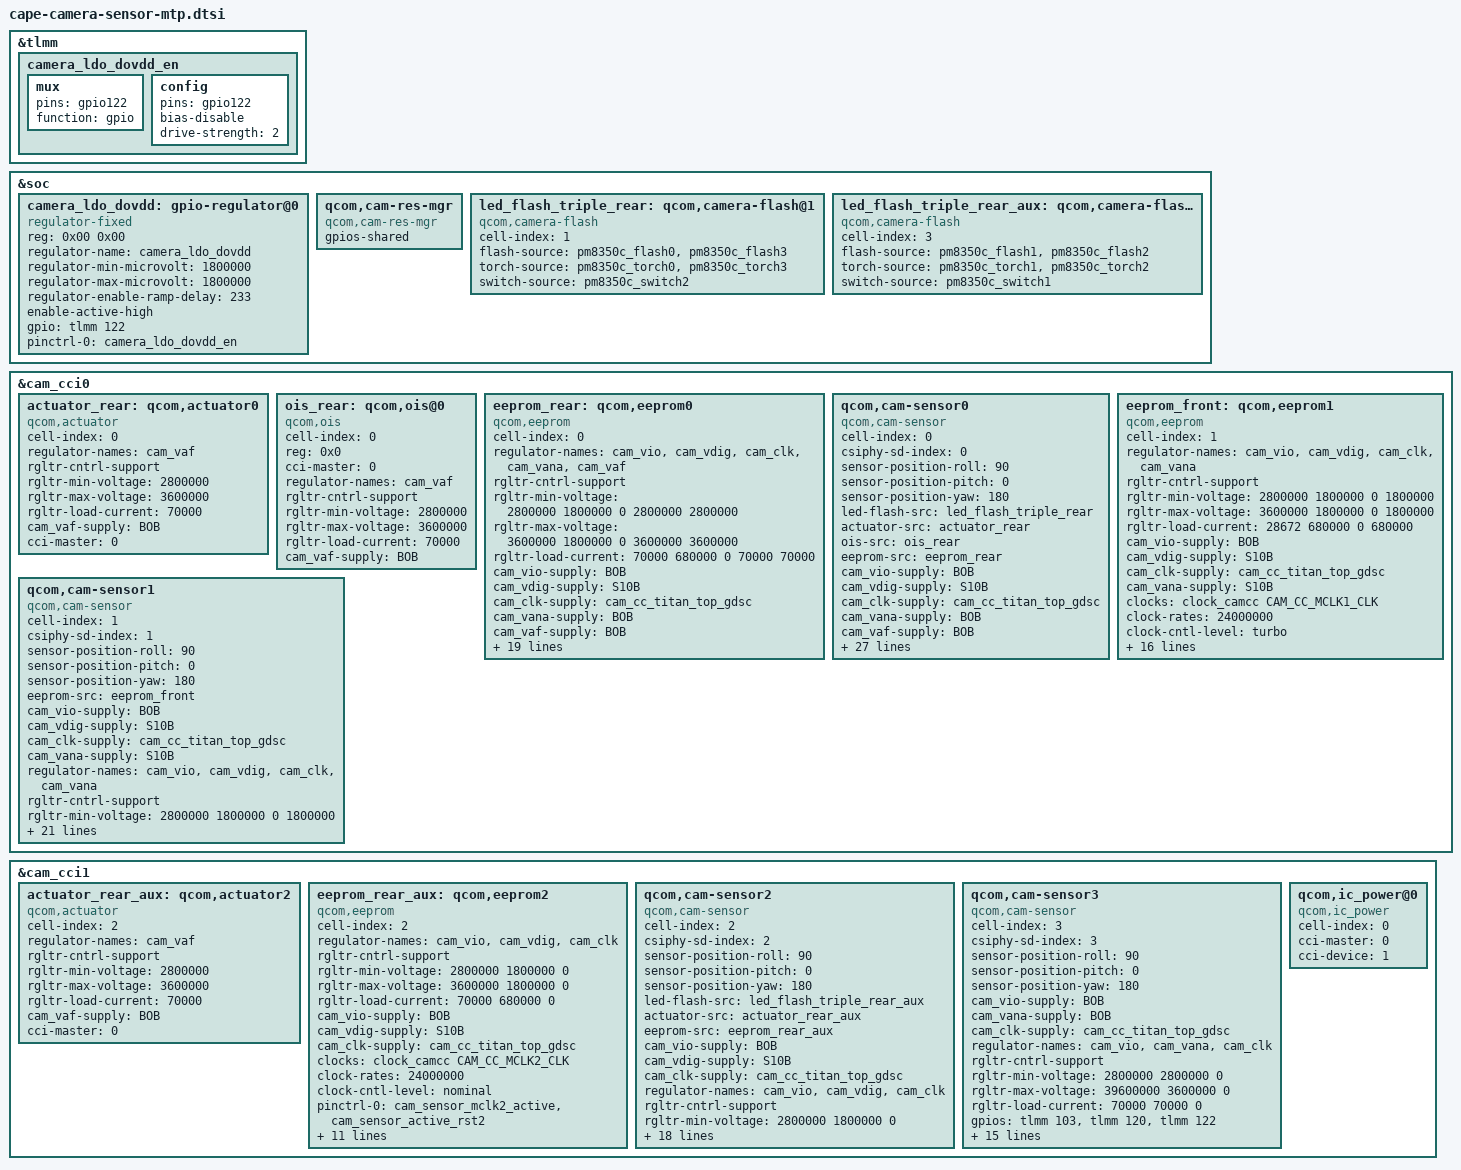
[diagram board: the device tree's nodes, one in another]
// SPDX-License-Identifier: BSD-3-Clause
/*
 * Copyright (c) 2022-2023, Qualcomm Innovation Center, Inc. All rights reserved.
 */

#include <dt-bindings/clock/qcom,camcc-waipio.h>
#include <dt-bindings/msm-camera.h>

&tlmm {
	camera_ldo_dovdd_en: camera_ldo_dovdd_en {
		mux {
			pins = "gpio122";
			function = "gpio";
		};

		config {
			pins = "gpio122";
			bias-disable; /* No PULL */
			drive-strength = <2>; /* 2 MA */
		};
	};
};

&soc {
	camera_ldo_dovdd: gpio-regulator@0 {
		compatible = "regulator-fixed";
		reg = <0x00 0x00>;
		regulator-name = "camera_ldo_dovdd";
		regulator-min-microvolt = <1800000>;
		regulator-max-microvolt = <1800000>;
		regulator-enable-ramp-delay = <233>;
		enable-active-high;
		gpio = <&tlmm 122 0>;
		pinctrl-names = "default";
		pinctrl-0 = <&camera_ldo_dovdd_en>;
	};

	qcom,cam-res-mgr {
		compatible = "qcom,cam-res-mgr";
		status = "ok";
		gpios-shared;
	};

	led_flash_triple_rear: qcom,camera-flash@1 {
		cell-index = <1>;
		compatible = "qcom,camera-flash";
		flash-source = <&pm8350c_flash0 &pm8350c_flash3>;
		torch-source = <&pm8350c_torch0 &pm8350c_torch3>;
		switch-source = <&pm8350c_switch2>;
		status = "ok";
	};

	led_flash_triple_rear_aux: qcom,camera-flash@3 {
		cell-index = <3>;
		compatible = "qcom,camera-flash";
		flash-source = <&pm8350c_flash1 &pm8350c_flash2>;
		torch-source = <&pm8350c_torch1 &pm8350c_torch2>;
		switch-source = <&pm8350c_switch1>;
		status = "ok";
	};
};

&cam_cci0 {
	actuator_rear: qcom,actuator0 {
		cell-index = <0>;
		regulator-names = "cam_vaf";
		rgltr-cntrl-support;
		rgltr-min-voltage = <2800000>;
		rgltr-max-voltage = <3600000>;
		rgltr-load-current = <70000>;
		cam_vaf-supply = <&BOB>;
		compatible = "qcom,actuator";
		cci-master = <0>;
	};

	ois_rear: qcom,ois@0 {
		cell-index = <0>;
		reg = <0x0>;
		compatible = "qcom,ois";
		cci-master = <0>;
		regulator-names = "cam_vaf";
		rgltr-cntrl-support;
		rgltr-min-voltage = <2800000>;
		rgltr-max-voltage = <3600000>;
		rgltr-load-current = <70000>;
		cam_vaf-supply = <&BOB>;
		status = "ok";
	};

	eeprom_rear: qcom,eeprom0 {
		cell-index = <0>;
		regulator-names = "cam_vio", "cam_vdig", "cam_clk", "cam_vana", "cam_vaf";
		rgltr-cntrl-support;
		rgltr-min-voltage = <2800000 1800000 0 2800000 2800000>;
		rgltr-max-voltage = <3600000 1800000 0 3600000 3600000>;
		rgltr-load-current = <70000 680000 0 70000 70000>;
		cam_vio-supply = <&BOB>;
		cam_vdig-supply = <&S10B>;
		cam_clk-supply = <&cam_cc_titan_top_gdsc>;
		cam_vana-supply = <&BOB>;
		cam_vaf-supply = <&BOB>;
		clocks = <&clock_camcc CAM_CC_MCLK0_CLK>;
		clock-names = "cam_clk";
		clock-rates = <24000000>;
		clock-cntl-level = "nominal";
		pinctrl-names = "cam_default", "cam_suspend";
		pinctrl-0 = <&cam_sensor_mclk0_active &cam_sensor_active_rst0>;
		pinctrl-1 = <&cam_sensor_mclk0_suspend &cam_sensor_suspend_rst0>;
		gpios = <&tlmm 100 0>,
			<&tlmm 25 0>,
			<&tlmm 122 0>,
			<&tlmm 129 0>,
			<&tlmm 124 0>;
		gpio-reset = <1>;
		gpio-vio = <2>;
		gpio-vdig = <3>;
		gpio-vaf = <4>;
		gpio-req-tbl-num = <0 1 2 3 4>;
		gpio-req-tbl-flags = <1 0 0 0 0>;
		gpio-req-tbl-label = "CAMIF_MCLK0",
			"CAM_RESET0",
			"CAM_VDDIO0",
			"CAM_DVDD0",
			"CAM_VAF0";
		gpio-no-mux = <0>;
		status = "ok";
		compatible = "qcom,eeprom";
		cci-master = <0>;
	};

	qcom,cam-sensor0 {
		cell-index = <0>;
		compatible = "qcom,cam-sensor";
		csiphy-sd-index = <0>;
		sensor-position-roll = <90>;
		sensor-position-pitch = <0>;
		sensor-position-yaw = <180>;
		led-flash-src = <&led_flash_triple_rear>;
		actuator-src = <&actuator_rear>;
		ois-src = <&ois_rear>;
		eeprom-src = <&eeprom_rear>;
		cam_vio-supply = <&BOB>;
		cam_vdig-supply = <&S10B>;
		cam_clk-supply = <&cam_cc_titan_top_gdsc>;
		cam_vana-supply = <&BOB>;
		cam_vaf-supply = <&BOB>;
		regulator-names = "cam_vio", "cam_vdig", "cam_clk", "cam_vana", "cam_vaf";
		rgltr-cntrl-support;
		rgltr-min-voltage = <2800000 1800000 0 2800000 2800000>;
		rgltr-max-voltage = <3600000 1800000 0 3600000 3600000>;
		rgltr-load-current = <70000 680000 0 70000 70000>;
		gpios = <&tlmm 100 0>,
			<&tlmm 25 0>,
			<&tlmm 122 0>,
			<&tlmm 129 0>,
			<&tlmm 124 0>;
		gpio-reset = <1>;
		gpio-vio = <2>;
		gpio-vdig = <3>;
		gpio-vaf = <4>;
		gpio-req-tbl-num = <0 1 2 3 4>;
		gpio-req-tbl-flags = <1 0 0 0 0>;
		gpio-req-tbl-label = "CAMIF_MCLK0",
			"CAM_RESET0",
			"CAM_VDDIO0",
			"CAM_DVDD0",
			"CAM_VAF0";
		gpio-no-mux = <0>;
		pinctrl-names = "cam_default", "cam_suspend";
		pinctrl-0 = <&cam_sensor_mclk0_active &cam_sensor_active_rst0>;
		pinctrl-1 = <&cam_sensor_mclk0_suspend &cam_sensor_suspend_rst0>;
		clocks = <&clock_camcc CAM_CC_MCLK0_CLK>;
		clock-names = "cam_clk";
		clock-rates = <24000000>;
		clock-cntl-level = "nominal";
		status = "ok";
		cci-master = <0>;
	};

	eeprom_front: qcom,eeprom1 {
		cell-index = <1>;
		regulator-names = "cam_vio", "cam_vdig", "cam_clk", "cam_vana";
		rgltr-cntrl-support;
		rgltr-min-voltage = <2800000 1800000 0 1800000>;
		rgltr-max-voltage = <3600000 1800000 0 1800000>;
		rgltr-load-current = <28672 680000 0 680000>;
		cam_vio-supply = <&BOB>;
		cam_vdig-supply = <&S10B>;
		cam_clk-supply = <&cam_cc_titan_top_gdsc>;
		cam_vana-supply = <&S10B>;
		clocks = <&clock_camcc CAM_CC_MCLK1_CLK>;
		clock-names = "cam_clk";
		clock-rates = <24000000>;
		clock-cntl-level = "turbo";
		pinctrl-names = "cam_default", "cam_suspend";
		pinctrl-0 = <&cam_sensor_mclk1_active &cam_sensor_active_rst1>;
		pinctrl-1 = <&cam_sensor_mclk1_suspend &cam_sensor_suspend_rst1>;
		gpios = <&tlmm 101 0>,
			<&tlmm 24 0>,
			<&tlmm 122 0>,
			<&tlmm 9 0>,
			<&tlmm 10 0>;
		gpio-reset = <1>;
		gpio-vio = <2>;
		gpio-vdig = <3>;
		gpio-vana = <4>;
		gpio-req-tbl-num = <0 1 2 3 4>;
		gpio-req-tbl-flags = <1 0 0 0 0>;
		gpio-req-tbl-label = "CAMIF_MCLK1",
			"CAM_RESET1",
			"CAM_VDDIO1",
			"CAM_DVDD1",
			"CAM_AVDD1";
		gpio-no-mux = <0>;
		status = "ok";
		compatible = "qcom,eeprom";
		cci-master = <1>;
	};

	qcom,cam-sensor1 {
		cell-index = <1>;
		compatible = "qcom,cam-sensor";
		csiphy-sd-index = <1>;
		sensor-position-roll = <90>;
		sensor-position-pitch = <0>;
		sensor-position-yaw = <180>;
		eeprom-src = <&eeprom_front>;
		cam_vio-supply = <&BOB>;
		cam_vdig-supply = <&S10B>;
		cam_clk-supply = <&cam_cc_titan_top_gdsc>;
		cam_vana-supply = <&S10B>;
		regulator-names = "cam_vio", "cam_vdig", "cam_clk", "cam_vana";
		rgltr-cntrl-support;
		rgltr-min-voltage = <2800000 1800000 0 1800000>;
		rgltr-max-voltage = <3600000 1800000 0 1800000>;
		rgltr-load-current = <28672 680000 0 680000>;
		gpios = <&tlmm 101 0>,
			<&tlmm 24 0>,
			<&tlmm 122 0>,
			<&tlmm 9 0>,
			<&tlmm 10 0>;
		gpio-reset = <1>;
		gpio-vio = <2>;
		gpio-vdig = <3>;
		gpio-vana = <4>;
		gpio-req-tbl-num = <0 1 2 3 4>;
		gpio-req-tbl-flags = <1 0 0 0 0>;
		gpio-req-tbl-label = "CAMIF_MCLK1",
			"CAM_RESET1",
			"CAM_VDDIO1",
			"CAM_DVDD1",
			"CAM_AVDD1";
		gpio-no-mux = <0>;
		pinctrl-names = "cam_default", "cam_suspend";
		pinctrl-0 = <&cam_sensor_mclk1_active &cam_sensor_active_rst1>;
		pinctrl-1 = <&cam_sensor_mclk1_suspend &cam_sensor_suspend_rst1>;
		clocks = <&clock_camcc CAM_CC_MCLK1_CLK>;
		clock-names = "cam_clk";
		clock-rates = <24000000>;
		clock-cntl-level = "turbo";
		status = "ok";
		cci-master = <1>;
	};
};

&cam_cci1 {
	actuator_rear_aux: qcom,actuator2 {
		cell-index = <2>;
		regulator-names = "cam_vaf";
		rgltr-cntrl-support;
		rgltr-min-voltage = <2800000>;
		rgltr-max-voltage = <3600000>;
		rgltr-load-current = <70000>;
		cam_vaf-supply = <&BOB>;
		compatible = "qcom,actuator";
		cci-master = <0>;
	};

	eeprom_rear_aux: qcom,eeprom2 {
		cell-index = <2>;
		regulator-names = "cam_vio", "cam_vdig", "cam_clk";
		rgltr-cntrl-support;
		rgltr-min-voltage = <2800000 1800000 0>;
		rgltr-max-voltage = <3600000 1800000 0>;
		rgltr-load-current = <70000 680000 0>;
		cam_vio-supply = <&BOB>;
		cam_vdig-supply = <&S10B>;
		cam_clk-supply = <&cam_cc_titan_top_gdsc>;
		clocks = <&clock_camcc CAM_CC_MCLK2_CLK>;
		clock-names = "cam_clk";
		clock-rates = <24000000>;
		clock-cntl-level = "nominal";
		pinctrl-names = "cam_default", "cam_suspend";
		pinctrl-0 = <&cam_sensor_mclk2_active &cam_sensor_active_rst2>;
		pinctrl-1 = <&cam_sensor_mclk2_suspend &cam_sensor_suspend_rst2>;
		gpios = <&tlmm 102 0>,
			<&tlmm 117 0>,
			<&tlmm 122 0>;
		gpio-reset = <1>;
		gpio-vio = <2>;
		gpio-req-tbl-num = <0 1 2>;
		gpio-req-tbl-flags = <1 0 0>;
		gpio-req-tbl-label = "CAMIF_MCLK2",
			"CAM_RESET2",
			"CAM_VIO2";
		gpio-no-mux = <0>;
		status = "ok";
		compatible = "qcom,eeprom";
		cci-master = <0>;
	};

	qcom,cam-sensor2 {
		cell-index = <2>;
		compatible = "qcom,cam-sensor";
		csiphy-sd-index = <2>;
		sensor-position-roll = <90>;
		sensor-position-pitch = <0>;
		sensor-position-yaw = <180>;
		led-flash-src = <&led_flash_triple_rear_aux>;
		actuator-src = <&actuator_rear_aux>;
		eeprom-src = <&eeprom_rear_aux>;
		cam_vio-supply = <&BOB>;
		cam_vdig-supply = <&S10B>;
		cam_clk-supply = <&cam_cc_titan_top_gdsc>;
		regulator-names = "cam_vio", "cam_vdig", "cam_clk";
		rgltr-cntrl-support;
		rgltr-min-voltage = <2800000 1800000 0>;
		rgltr-max-voltage = <3600000 1800000 0>;
		rgltr-load-current = <70000 680000 0>;
		gpios = <&tlmm 102 0>,
			<&tlmm 117 0>,
			<&tlmm 122 0>;
		gpio-reset = <1>;
		gpio-vio = <2>;
		gpio-req-tbl-num = <0 1 2>;
		gpio-req-tbl-flags = <1 0 0>;
		gpio-req-tbl-label = "CAMIF_MCLK2",
			"CAM_RESET2",
			"CAM_VIO2";
		gpio-no-mux = <0>;
		pinctrl-names = "cam_default", "cam_suspend";
		pinctrl-0 = <&cam_sensor_mclk2_active &cam_sensor_active_rst2>;
		pinctrl-1 = <&cam_sensor_mclk2_suspend &cam_sensor_suspend_rst2>;
		clocks = <&clock_camcc CAM_CC_MCLK2_CLK>;
		clock-names = "cam_clk";
		clock-rates = <24000000>;
		clock-cntl-level = "nominal";
		status = "ok";
		cci-master = <0>;
	};

	qcom,cam-sensor3 {
		cell-index = <3>;
		compatible = "qcom,cam-sensor";
		csiphy-sd-index = <3>;
		sensor-position-roll = <90>;
		sensor-position-pitch = <0>;
		sensor-position-yaw = <180>;
		cam_vio-supply = <&BOB>;
		cam_vana-supply = <&BOB>;
		cam_clk-supply = <&cam_cc_titan_top_gdsc>;
		regulator-names = "cam_vio", "cam_vana", "cam_clk";
		rgltr-cntrl-support;
		rgltr-min-voltage = <2800000 2800000 0>;
		rgltr-max-voltage = <39600000 3600000 0>;
		rgltr-load-current = <70000 70000 0>;
		gpios = <&tlmm 103 0>,
			<&tlmm 120 0>,
			<&tlmm 122 0>;
		gpio-reset = <1>;
		gpio-vio = <2>;
		gpio-req-tbl-num = <0 1 2>;
		gpio-req-tbl-flags = <1 0 0>;
		gpio-req-tbl-label = "CAMIF_MCLK3",
			"CAM_RESET3",
			"CAM_VIO3";
		gpio-no-mux = <0>;
		pinctrl-names = "cam_default", "cam_suspend";
		pinctrl-0 = <&cam_sensor_mclk3_active &cam_sensor_active_rst3>;
		pinctrl-1 = <&cam_sensor_mclk3_suspend &cam_sensor_suspend_rst3>;
		clocks = <&clock_camcc CAM_CC_MCLK3_CLK>;
		clock-names = "cam_clk";
		clock-rates = <24000000>;
		clock-cntl-level = "nominal";
		status = "ok";
		cci-master = <0>;
	};

	qcom,ic_power@0 {
		cell-index = <0>;
		compatible = "qcom,ic_power";
		cci-master = <0>;
		cci-device = <1>;
		status = "ok";
	};
};
